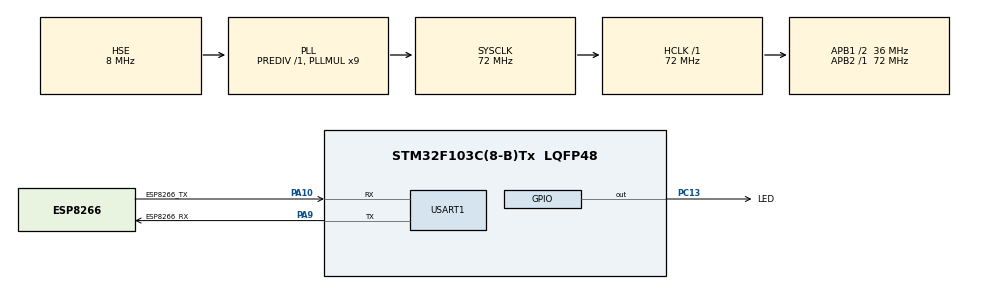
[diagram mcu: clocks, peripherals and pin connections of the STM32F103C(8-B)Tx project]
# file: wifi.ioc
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Mcu.Family=STM32F1
RCC.PLLSourceVirtual=RCC_PLLSOURCE_HSE
PD1-OSC_OUT.Mode=HSE-External-Oscillator
PA10.Mode=Asynchronous
PA9.GPIO_Label=ESP8266_RX
PC13-TAMPER-RTC.Signal=GPIO_Output
NVIC.TIM1_UP_IRQn=true\:0\:0\:false\:false\:true\:false\:true
PD0-OSC_IN.Signal=RCC_OSC_IN
RCC.APB1CLKDivider=RCC_HCLK_DIV2
RCC.SYSCLKSource=RCC_SYSCLKSOURCE_PLLCLK
ProjectManager.StackSize=0x400
PD1-OSC_OUT.Signal=RCC_OSC_OUT
PA13.Signal=SYS_JTMS-SWDIO
PA9.Mode=Asynchronous
ProjectManager.TargetToolchain=STM32CubeIDE
RCC.HCLKFreq_Value=72000000
RCC.APB2TimFreq_Value=72000000
PA9.Signal=USART1_TX
RCC.USBFreq_Value=72000000
RCC.AHBFreq_Value=72000000
PD0-OSC_IN.Mode=HSE-External-Oscillator
board=custom
RCC.PLLMUL=RCC_PLL_MUL9
PC13-TAMPER-RTC.GPIO_Label=LED
RCC.APB2Freq_Value=72000000
PA14.Mode=Serial_Wire
VP_SYS_VS_tim1.Mode=TIM1
PA10.GPIO_Label=ESP8266_TX
PA13.Mode=Serial_Wire
Mcu.Name=STM32F103C(8-B)Tx
RCC.SYSCLKFreq_VALUE=72000000
Mcu.Package=LQFP48
NVIC.TimeBase=TIM1_UP_IRQn
USART1.VirtualMode=VM_ASYNC
NVIC.TimeBaseIP=TIM1
PA10.Signal=USART1_RX
PA14.Signal=SYS_JTCK-SWCLK
ProjectManager.HeapSize=0x200
NVIC.PriorityGroup=NVIC_PRIORITYGROUP_4
RCC.APB1TimFreq_Value=72000000
RCC.APB1Freq_Value=36000000

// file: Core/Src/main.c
/* USER CODE BEGIN Header */
/**

  The following program uses the UART to communicate with an ESP8266 microcontroller, which will connect to a Firebase database over WiFi.
  - The STM32 will send the "connect" command in order to connect to the WiFi network, and the ESP8266 will answer with "1" once the connection is successful
  - The STM32 will send the "get-led" command for the ESP8266 to query the database and return the led status
  - The STM32 will send the "set-count" command along with a value for the ESP8266 to update the database
  - The ESP8266 program was made in Arduino and is provided inside the ESP8266 folder

  */
/* USER CODE END Header */
#include "main.h"

/* USER CODE BEGIN Includes */
#include "FreeRTOS.h"
#include "task.h"
#include "semphr.h"
#include "stdio.h"
/* USER CODE END Includes */

UART_HandleTypeDef huart1;

void SystemClock_Config(void);
static void MX_GPIO_Init(void);
static void MX_USART1_UART_Init(void);

/* USER CODE BEGIN 0 */

SemaphoreHandle_t uart_mutex;

static void GetLed(void *pvParameters){

	uint8_t data;
	uint8_t command[] = "get-led";

	while(1){

		// Take the mutex to use the UART
		xSemaphoreTake(uart_mutex, portMAX_DELAY);

		// Send the command to get the led status
		HAL_UART_Transmit(&huart1, command, sizeof(command)-1, 1000);
		vTaskDelay(2000/portTICK_PERIOD_MS);

		// Wait for the response
		HAL_UART_Receive(&huart1, &data, 1, 1000);

		if (data == '0'){
			HAL_GPIO_WritePin(LED_GPIO_Port, LED_Pin, 1); // Turn off the led
		}

		if (data == '1') {
			HAL_GPIO_WritePin(LED_GPIO_Port, LED_Pin, 0); // Turn on the led
		}

		// Release the mutex
		xSemaphoreGive(uart_mutex);

		vTaskDelay(5000/portTICK_PERIOD_MS);
	}
}

static void SetCount(void *pvParameters){

	int count=0;
	uint8_t command[] = "set-count";
	char value[10];
	int value_length;

	while(1){

		count++;

		// Take the mutex to use the UART
		xSemaphoreTake(uart_mutex, portMAX_DELAY);

		// Send the command to set the count value
		HAL_UART_Transmit(&huart1, command, sizeof(command)-1, 1000);
		vTaskDelay(2000/portTICK_PERIOD_MS);

		// Convert the value to string and calculate the length
		sprintf(value, "%i", count);
		value_length=0;
		for (int i=0; i<sizeof(value); i++){
			if (value[i]==0) break;
			value_length++;
		}

		// Send the value
		HAL_UART_Transmit(&huart1, (uint8_t*)value, value_length, 1000);
		vTaskDelay(2000/portTICK_PERIOD_MS);

		// Release the mutex
		xSemaphoreGive(uart_mutex);

		vTaskDelay(10000/portTICK_PERIOD_MS);

	}
}

/* USER CODE END 0 */

int main(void)
{

  /* MCU Configuration--------------------------------------------------------*/

  /* Reset of all peripherals, Initializes the Flash interface and the Systick. */
  HAL_Init();

  /* Configure the system clock */
  SystemClock_Config();

  /* Initialize all configured peripherals */
  MX_GPIO_Init();
  MX_USART1_UART_Init();
  /* USER CODE BEGIN 2 */

  uint8_t data;
  uint8_t command[] = "connect";

  // Tells ESP8266 to connect to WiFi network
  HAL_UART_Transmit(&huart1, command, sizeof(command)-1, HAL_MAX_DELAY);

  // Receives data from UART until it gets '1' which means it is connected
  do {
	  HAL_UART_Receive(&huart1, &data, 1, HAL_MAX_DELAY);
  } while(data != '1');

  uart_mutex = xSemaphoreCreateMutex();

  xTaskCreate(GetLed, (char *) "",
  		        configMINIMAL_STACK_SIZE,
  				NULL,
  				(tskIDLE_PRIORITY + 1UL),
  		        NULL);

  xTaskCreate(SetCount, (char *) "",
    		    configMINIMAL_STACK_SIZE,
				NULL,
    			(tskIDLE_PRIORITY + 1UL),
    		    NULL);

  vTaskStartScheduler();

  /* USER CODE END 2 */

  /* Infinite loop */
  while (1)
  {

  }
}

void SystemClock_Config(void)
{
  RCC_OscInitTypeDef RCC_OscInitStruct = {0};
  RCC_ClkInitTypeDef RCC_ClkInitStruct = {0};

  /** Initializes the RCC Oscillators according to the specified parameters
  * in the RCC_OscInitTypeDef structure.
  */
  RCC_OscInitStruct.OscillatorType = RCC_OSCILLATORTYPE_HSE;
  RCC_OscInitStruct.HSEState = RCC_HSE_ON;
  RCC_OscInitStruct.HSEPredivValue = RCC_HSE_PREDIV_DIV1;
  RCC_OscInitStruct.HSIState = RCC_HSI_ON;
  RCC_OscInitStruct.PLL.PLLState = RCC_PLL_ON;
  RCC_OscInitStruct.PLL.PLLSource = RCC_PLLSOURCE_HSE;
  RCC_OscInitStruct.PLL.PLLMUL = RCC_PLL_MUL9;
  if (HAL_RCC_OscConfig(&RCC_OscInitStruct) != HAL_OK)
  {
    Error_Handler();
  }
  /** Initializes the CPU, AHB and APB buses clocks
  */
  RCC_ClkInitStruct.ClockType = RCC_CLOCKTYPE_HCLK|RCC_CLOCKTYPE_SYSCLK
                              |RCC_CLOCKTYPE_PCLK1|RCC_CLOCKTYPE_PCLK2;
  RCC_ClkInitStruct.SYSCLKSource = RCC_SYSCLKSOURCE_PLLCLK;
  RCC_ClkInitStruct.AHBCLKDivider = RCC_SYSCLK_DIV1;
  RCC_ClkInitStruct.APB1CLKDivider = RCC_HCLK_DIV2;
  RCC_ClkInitStruct.APB2CLKDivider = RCC_HCLK_DIV1;

  if (HAL_RCC_ClockConfig(&RCC_ClkInitStruct, FLASH_LATENCY_2) != HAL_OK)
  {
    Error_Handler();
  }
}

static void MX_USART1_UART_Init(void)
{

  huart1.Instance = USART1;
  huart1.Init.BaudRate = 115200;
  huart1.Init.WordLength = UART_WORDLENGTH_8B;
  huart1.Init.StopBits = UART_STOPBITS_1;
  huart1.Init.Parity = UART_PARITY_NONE;
  huart1.Init.Mode = UART_MODE_TX_RX;
  huart1.Init.HwFlowCtl = UART_HWCONTROL_NONE;
  huart1.Init.OverSampling = UART_OVERSAMPLING_16;
  if (HAL_UART_Init(&huart1) != HAL_OK)
  {
    Error_Handler();
  }

}

static void MX_GPIO_Init(void)
{
  GPIO_InitTypeDef GPIO_InitStruct = {0};

  /* GPIO Ports Clock Enable */
  __HAL_RCC_GPIOC_CLK_ENABLE();
  __HAL_RCC_GPIOD_CLK_ENABLE();
  __HAL_RCC_GPIOA_CLK_ENABLE();

  /*Configure GPIO pin Output Level */
  HAL_GPIO_WritePin(LED_GPIO_Port, LED_Pin, GPIO_PIN_RESET);

  /*Configure GPIO pin : LED_Pin */
  GPIO_InitStruct.Pin = LED_Pin;
  GPIO_InitStruct.Mode = GPIO_MODE_OUTPUT_PP;
  GPIO_InitStruct.Pull = GPIO_NOPULL;
  GPIO_InitStruct.Speed = GPIO_SPEED_FREQ_LOW;
  HAL_GPIO_Init(LED_GPIO_Port, &GPIO_InitStruct);

}

 /**
  * @brief  Period elapsed callback in non blocking mode
  * @note   This function is called  when TIM1 interrupt took place, inside
  * HAL_TIM_IRQHandler(). It makes a direct call to HAL_IncTick() to increment
  * a global variable "uwTick" used as application time base.
  * @param  htim : TIM handle
  * @retval None
  */
void HAL_TIM_PeriodElapsedCallback(TIM_HandleTypeDef *htim)
{
  if (htim->Instance == TIM1) {
    HAL_IncTick();
  }
}

void Error_Handler(void)
{
  __disable_irq();
  while (1)
  {
  }
}

/************************ (C) COPYRIGHT STMicroelectronics *****END OF FILE****/
